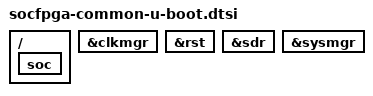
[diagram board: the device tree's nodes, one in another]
// SPDX-License-Identifier: GPL-2.0+
/*
 * U-Boot additions
 *
 * Copyright (c) 2019 Simon Goldschmidt
 */
/{
	soc {
		u-boot,dm-all;
	};
};

&clkmgr {
	u-boot,dm-all;
};

&rst {
	u-boot,dm-all;
};

&sdr {
	u-boot,dm-all;
};

&sysmgr {
	u-boot,dm-all;
};
